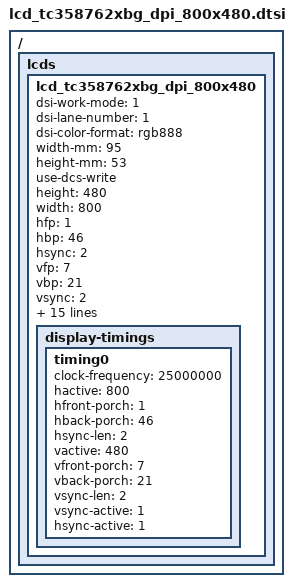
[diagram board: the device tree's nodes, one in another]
// SPDX-License-Identifier: GPL-2.0

/ {
	lcds: lcds {
		lcd_tc358762xbg_dpi_800x480: lcd_tc358762xbg_dpi_800x480 {
		dsi-work-mode = <1>; /* video burst mode*/
		dsi-lane-number = <1>;
		dsi-color-format = "rgb888";
		width-mm = <95>;
		height-mm = <53>;
		use-dcs-write;

		/*mipi info*/
		height = <480>;
		width = <800>;
		hfp = <1>;
		hbp = <46>;
		hsync = <2>;
		vfp = <7>;
		vbp = <21>;
		vsync = <2>;
		fps = <55>;
		work-mode = <0>;
		rgb-mode = <3>;
		lane-number = <1>;
		phy-bit-clock = <700000000>;
		split-enable = <0>;
		eotp-enable = <0>;
		burst-mode = <2>;
		esd-check-enable = <0>;

		/* DSI_CMD, DSI_MODE, timeout, len, cmd */
		initial-command = [
			39 01 F0 01 11
			39 01 28 01 29
		];

		sleep-in-command = [
			39 01 78 01 28
			39 01 78 01 10
		];

		sleep-out-command = [
			39 01 96 01 11
			39 01 32 01 29
		];

		display-timings {
				timing0 {
					clock-frequency = <25000000>;
					hactive = <800>;
					hfront-porch = <1>;
					hback-porch = <46>;
					hsync-len = <2>;
					vactive = <480>;
					vfront-porch = <7>;
					vback-porch = <21>;
					vsync-len = <2>;
					vsync-active = <1>;
					hsync-active = <1>;
				};
			};
		};
	};
};
